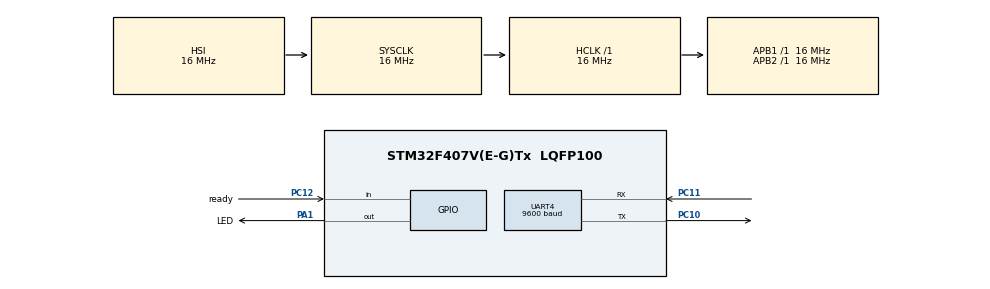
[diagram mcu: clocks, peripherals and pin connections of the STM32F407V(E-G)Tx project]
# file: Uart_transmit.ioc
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Mcu.Family=STM32F4
Mcu.Name=STM32F407V(E-G)Tx
Mcu.Package=LQFP100
NVIC.PriorityGroup=NVIC_PRIORITYGROUP_4
PA1.GPIO_Label=LED
PA1.Signal=GPIO_Output
PC10.Mode=Asynchronous
PC10.Signal=UART4_TX
PC11.Mode=Asynchronous
PC11.Signal=UART4_RX
PC12.GPIO_Label=ready
PC12.Signal=GPIO_Input
ProjectManager.HeapSize=0x200
ProjectManager.StackSize=0x400
ProjectManager.TargetToolchain=MDK-ARM V5.32
RCC.AHBFreq_Value=16000000
RCC.APB1Freq_Value=16000000
RCC.APB2Freq_Value=16000000
RCC.CortexFreq_Value=16000000
RCC.HSE_VALUE=25000000
RCC.HSI_VALUE=16000000
RCC.LSE_VALUE=32768
RCC.SYSCLKFreq_VALUE=16000000
RCC.VCOOutputFreq_Value=192000000
UART4.BaudRate=9600
UART4.VirtualMode=Asynchronous
board=custom

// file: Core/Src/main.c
/* USER CODE BEGIN Header */
/**
  ******************************************************************************
  * @file           : main.c
  * @brief          : Main program body
  ******************************************************************************
  * @attention
  *
  * <h2><center>&copy; Copyright (c) 2021 STMicroelectronics.
  * All rights reserved.</center></h2>
  *
  * This software component is licensed by ST under BSD 3-Clause license,
  * the "License"; You may not use this file except in compliance with the
  * License. You may obtain a copy of the License at:
  *                        opensource.org/licenses/BSD-3-Clause
  *
  ******************************************************************************
  */
/* USER CODE END Header */
#include "main.h"
#include "usart.h"
#include "gpio.h"

/* USER CODE BEGIN PV */
uint8_t rcvData[8] = {0xAC,0xAA,0xAB,0xAD,0xAE,0xAF,0xA1,0xA2};
uint8_t ready;
/* USER CODE END PV */

void SystemClock_Config(void);

int main(void)
{

  /* MCU Configuration--------------------------------------------------------*/

  /* Reset of all peripherals, Initializes the Flash interface and the Systick. */
  HAL_Init();

  /* Configure the system clock */
  SystemClock_Config();

  /* Initialize all configured peripherals */
  MX_GPIO_Init();
  MX_UART4_Init();

  /* Infinite loop */
  while (1)
  {

    /* USER CODE BEGIN 3 */
		ready = HAL_GPIO_ReadPin(ready_GPIO_Port,ready_Pin);
		if(ready){
			if(1){
				HAL_UART_Transmit(&huart4,rcvData,8,10);
				HAL_GPIO_TogglePin(LED_GPIO_Port,LED_Pin);
			}
		}
		HAL_Delay(10);
  }
  /* USER CODE END 3 */
}

void SystemClock_Config(void)
{
  RCC_OscInitTypeDef RCC_OscInitStruct = {0};
  RCC_ClkInitTypeDef RCC_ClkInitStruct = {0};

  /** Configure the main internal regulator output voltage
  */
  __HAL_RCC_PWR_CLK_ENABLE();
  __HAL_PWR_VOLTAGESCALING_CONFIG(PWR_REGULATOR_VOLTAGE_SCALE1);
  /** Initializes the RCC Oscillators according to the specified parameters
  * in the RCC_OscInitTypeDef structure.
  */
  RCC_OscInitStruct.OscillatorType = RCC_OSCILLATORTYPE_HSI;
  RCC_OscInitStruct.HSIState = RCC_HSI_ON;
  RCC_OscInitStruct.HSICalibrationValue = RCC_HSICALIBRATION_DEFAULT;
  RCC_OscInitStruct.PLL.PLLState = RCC_PLL_NONE;
  if (HAL_RCC_OscConfig(&RCC_OscInitStruct) != HAL_OK)
  {
    Error_Handler();
  }
  /** Initializes the CPU, AHB and APB buses clocks
  */
  RCC_ClkInitStruct.ClockType = RCC_CLOCKTYPE_HCLK|RCC_CLOCKTYPE_SYSCLK
                              |RCC_CLOCKTYPE_PCLK1|RCC_CLOCKTYPE_PCLK2;
  RCC_ClkInitStruct.SYSCLKSource = RCC_SYSCLKSOURCE_HSI;
  RCC_ClkInitStruct.AHBCLKDivider = RCC_SYSCLK_DIV1;
  RCC_ClkInitStruct.APB1CLKDivider = RCC_HCLK_DIV1;
  RCC_ClkInitStruct.APB2CLKDivider = RCC_HCLK_DIV1;

  if (HAL_RCC_ClockConfig(&RCC_ClkInitStruct, FLASH_LATENCY_0) != HAL_OK)
  {
    Error_Handler();
  }
}

void Error_Handler(void)
{
  __disable_irq();
  while (1)
  {
  }
}

/************************ (C) COPYRIGHT STMicroelectronics *****END OF FILE****/
